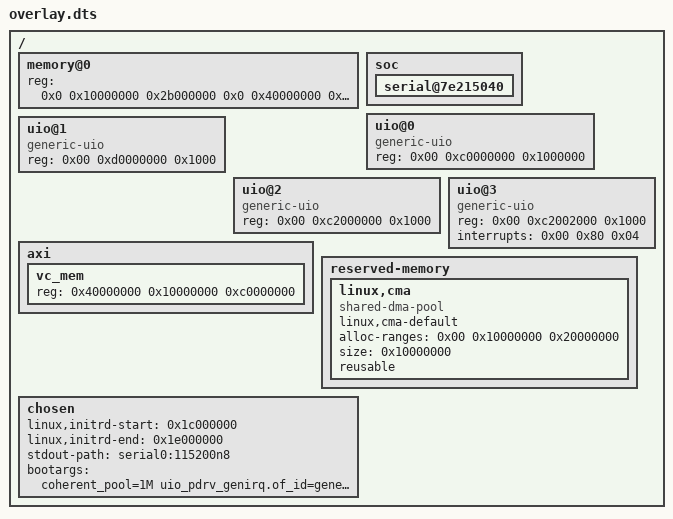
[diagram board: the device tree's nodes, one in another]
/*
 * Copyright 2025, UNSW
 *
 * SPDX-License-Identifier: BSD-2-Clause
 */

// added too bootargs maxcpus=1
//added the modprobe blacklist

/ {
    memory@0 {
		device_type = "memory";
		reg = <0x0 0x10000000 0x2b000000 0x0 0x40000000 0x80000000>;
	};

    // scb {
    //     ethernet@7d580000 {
    //         status = "disabled";
    //     };
    //     hdmi@7ef05700 {
    //         status = "disabled";
    //     };
    // };

    soc {
        // gpio@7e200000 {
        //     status = "okay";
        // };
        serial@7e215040 {
            status = "okay";
        };
        // mmc@7e300000 {
        //     status = "okay";
        // };
        // mmc@7e202000 {
        //     status = "okay";
        // };
        // serial@7e201000 {
        //     status = "disabled";
        //     bluetooth {
        //         status = "disabled";
        //     };
        // };
        // serial@7e201000 {
        //     status = "disabled";
        //     bluetooth {
        //         status = "disabled";
        //     };
        // };
    //     hdmi@7ef00700 {
    //         status = "disabled";
    //     };
    };

    uio@0 {
        compatible = "generic-uio\0uio";
        // Memory region for guest to write frames into 
        reg = <0x00 0xc0000000 0x1000000>;
    };

    uio@1 {
        compatible = "generic-uio\0uio";
        // VM -> Hypervisor interrupt for frame to client path. This physaddr remain unmapped in guest
        // Guest writes to this address when it want to notify the VMM.
        reg = <0x00 0xd0000000 0x1000>;
    };

    uio@2 {
        compatible = "generic-uio\0uio";
        // control data region
        reg = <0x00 0xc2000000 0x1000>;
    };
    
    uio@3 {
        compatible = "generic-uio\0uio";
        // control data region interrupt
        reg = <0x00 0xc2002000 0x1000>;
        // interrupt 128/160
        interrupts = <0x00 0x80 0x04>;
    };

    axi {
      vc_mem {
        reg = <0x40000000 0x10000000 0xc0000000>;
      };
    };

    reserved-memory {
      linux,cma {
        linux,cma-default;
        alloc-ranges = <0x00 0x10000000 0x20000000>;
        compatible = "shared-dma-pool";
        size = <0x10000000>;
        phandle = <0x5d>;
        reusable;
      };
    };

    chosen {
        linux,initrd-start = <0x1c000000>;
        linux,initrd-end = <0x1e000000>;
        stdout-path = "serial0:115200n8";
        // 32gb card root=PARTUUID=7d9e3605-02
        //16gb card  root=PARTUUID=1740494f-02
        // initcall_debug loglevel=8
        bootargs = "coherent_pool=1M uio_pdrv_genirq.of_id=generic-uio console=ttyS0,115200 vc_mem.mem_base=0x40000000 vc_mem.mem_size=0x10000000 cma_debug=on debug_pagealloc=on earlycon=uart8250,mmio32,0xfe215040 8250.nr_uarts=1 rw debug maxcpus=1 root=PARTUUID=1740494f-02 rootfstype=ext4 rootwait";
    };
};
